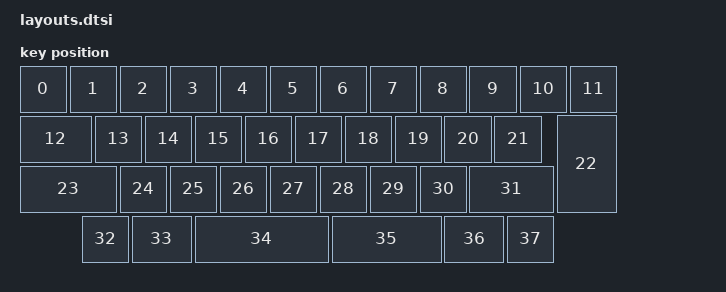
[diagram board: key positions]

#include <physical_layouts.dtsi>
/ {
    physical_layout0: physical_layout0 {
        compatible = "zmk,physical-layout";
        display-name = "Layout";
        keys
            = <&key_physical_attrs 100 100 (-50) 0 0 0 0>
			,<&key_physical_attrs 100 100 50 0 0 0 0>
			,<&key_physical_attrs 100 100 150 0 0 0 0>
			,<&key_physical_attrs 100 100 250 0 0 0 0>
			,<&key_physical_attrs 100 100 350 0 0 0 0>
			,<&key_physical_attrs 100 100 450 0 0 0 0>
			,<&key_physical_attrs 100 100 550 0 0 0 0>
			,<&key_physical_attrs 100 100 650 0 0 0 0>
			,<&key_physical_attrs 100 100 750 0 0 0 0>
			,<&key_physical_attrs 100 100 850 0 0 0 0>
			,<&key_physical_attrs 100 100 950 0 0 0 0>
			,<&key_physical_attrs 100 100 1050 0 0 0 0>
			,<&key_physical_attrs 150 100 (-50) 100 0 0 0>
			,<&key_physical_attrs 100 100 100 100 0 0 0>
			,<&key_physical_attrs 100 100 200 100 0 0 0>
			,<&key_physical_attrs 100 100 300 100 0 0 0>
			,<&key_physical_attrs 100 100 400 100 0 0 0>
			,<&key_physical_attrs 100 100 500 100 0 0 0>
			,<&key_physical_attrs 100 100 600 100 0 0 0>
			,<&key_physical_attrs 100 100 700 100 0 0 0>
			,<&key_physical_attrs 100 100 800 100 0 0 0>
			,<&key_physical_attrs 100 100 900 100 0 0 0>
			,<&key_physical_attrs 200 125 1150 100 9000 1150 100>
			,<&key_physical_attrs 200 100 (-50) 200 0 0 0>
			,<&key_physical_attrs 100 100 150 200 0 0 0>
			,<&key_physical_attrs 100 100 250 200 0 0 0>
			,<&key_physical_attrs 100 100 350 200 0 0 0>
			,<&key_physical_attrs 100 100 450 200 0 0 0>
			,<&key_physical_attrs 100 100 550 200 0 0 0>
			,<&key_physical_attrs 100 100 650 200 0 0 0>
			,<&key_physical_attrs 100 100 750 200 0 0 0>
			,<&key_physical_attrs 175 100 850 200 0 0 0>
			,<&key_physical_attrs 100 100 75 300 0 0 0>
			,<&key_physical_attrs 125 100 175 300 0 0 0>
			,<&key_physical_attrs 275 100 300 300 0 0 0>
			,<&key_physical_attrs 225 100 575 300 0 0 0>
			,<&key_physical_attrs 125 100 800 300 0 0 0>
			,<&key_physical_attrs 100 100 925 300 0 0 0>
            ;
    };
};
    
